VERSION ""

NS_ :

BS_:

BU_:

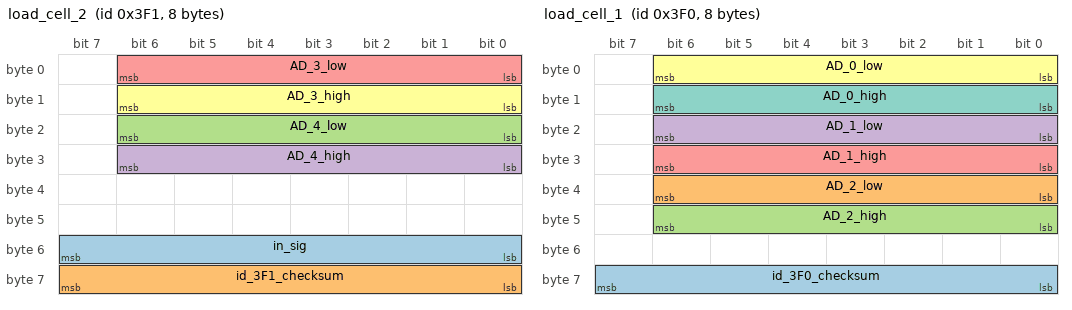
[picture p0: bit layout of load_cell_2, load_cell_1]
BO_ 1009 load_cell_2: 8 Vector__XXX
 SG_ in_sig : 48|8@1+ (1,0) [0|255] "" Vector__XXX
 SG_ id_3F1_checksum : 56|8@1+ (1,0) [0|255] "" Vector__XXX
 SG_ AD_4_low : 16|7@1+ (1,0) [0|127] "" Vector__XXX
 SG_ AD_4_high : 24|7@1+ (1,0) [0|127] "" Vector__XXX
 SG_ AD_3_low : 0|7@1+ (1,0) [0|127] "" Vector__XXX
 SG_ AD_3_high : 8|7@1+ (1,0) [0|127] "" Vector__XXX

BO_ 1008 load_cell_1: 8 Vector__XXX
 SG_ id_3F0_checksum : 56|8@1+ (1,0) [0|255] "" Vector__XXX
 SG_ AD_2_low : 32|7@1+ (1,0) [0|127] "" Vector__XXX
 SG_ AD_2_high : 40|7@1+ (1,0) [0|127] "" Vector__XXX
 SG_ AD_1_low : 16|7@1+ (1,0) [0|127] "" Vector__XXX
 SG_ AD_1_high : 24|7@1+ (1,0) [0|127] "" Vector__XXX
 SG_ AD_0_low : 0|7@1+ (1,0) [0|127] "" Vector__XXX
 SG_ AD_0_high : 8|7@1+ (1,0) [0|127] "" Vector__XXX

BA_DEF_  "BusType" STRING ;
BA_DEF_DEF_  "BusType" "CAN";
